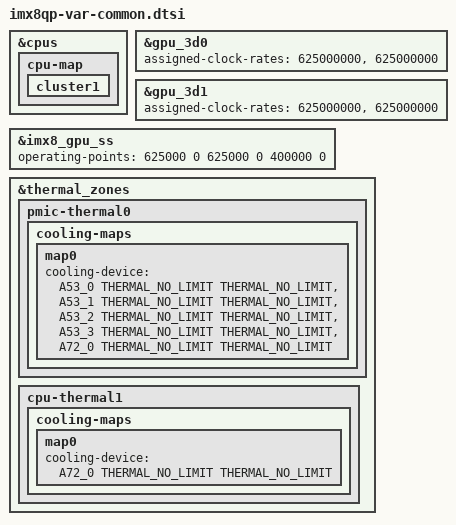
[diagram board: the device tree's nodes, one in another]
/*
 * Copyright (C) 2016 Freescale Semiconductor, Inc.
 * Copyright 2017 NXP
 * Copyright 2021 Variscite Ltd.
 *
 * This program is free software; you can redistribute it and/or
 * modify it under the terms of the GNU General Public License
 * as published by the Free Software Foundation; either version 2
 * of the License, or (at your option) any later version.
 *
 * This program is distributed in the hope that it will be useful,
 * but WITHOUT ANY WARRANTY; without even the implied warranty of
 * MERCHANTABILITY or FITNESS FOR A PARTICULAR PURPOSE.  See the
 * GNU General Public License for more details.
 */

&cpus {
	cpu-map {
		cluster1 {
			/delete-node/ core1;
		};
	};
	/delete-node/ cpu@101;
};

&gpu_3d0 {
      assigned-clock-rates = <625000000>, <625000000>;
};

&gpu_3d1 {
      assigned-clock-rates = <625000000>, <625000000>;
};

&imx8_gpu_ss {/*<freq-kHz vol-uV>*/
	operating-points = <
	/*nominal*/	625000  0
				625000  0
/*underdrive*/	400000  0  /*core/shader clock share the same frequency on underdrive mode*/
	>;
};

&thermal_zones {
	pmic-thermal0 {
		cooling-maps {
			map0 {
				cooling-device =
				<&A53_0 THERMAL_NO_LIMIT THERMAL_NO_LIMIT>,
				<&A53_1 THERMAL_NO_LIMIT THERMAL_NO_LIMIT>,
				<&A53_2 THERMAL_NO_LIMIT THERMAL_NO_LIMIT>,
				<&A53_3 THERMAL_NO_LIMIT THERMAL_NO_LIMIT>,
				<&A72_0 THERMAL_NO_LIMIT THERMAL_NO_LIMIT>;
			};
		};
	};
	cpu-thermal1 {
		cooling-maps {
			map0 {
				cooling-device =
				<&A72_0 THERMAL_NO_LIMIT THERMAL_NO_LIMIT>;
			};
		};
	};
};
